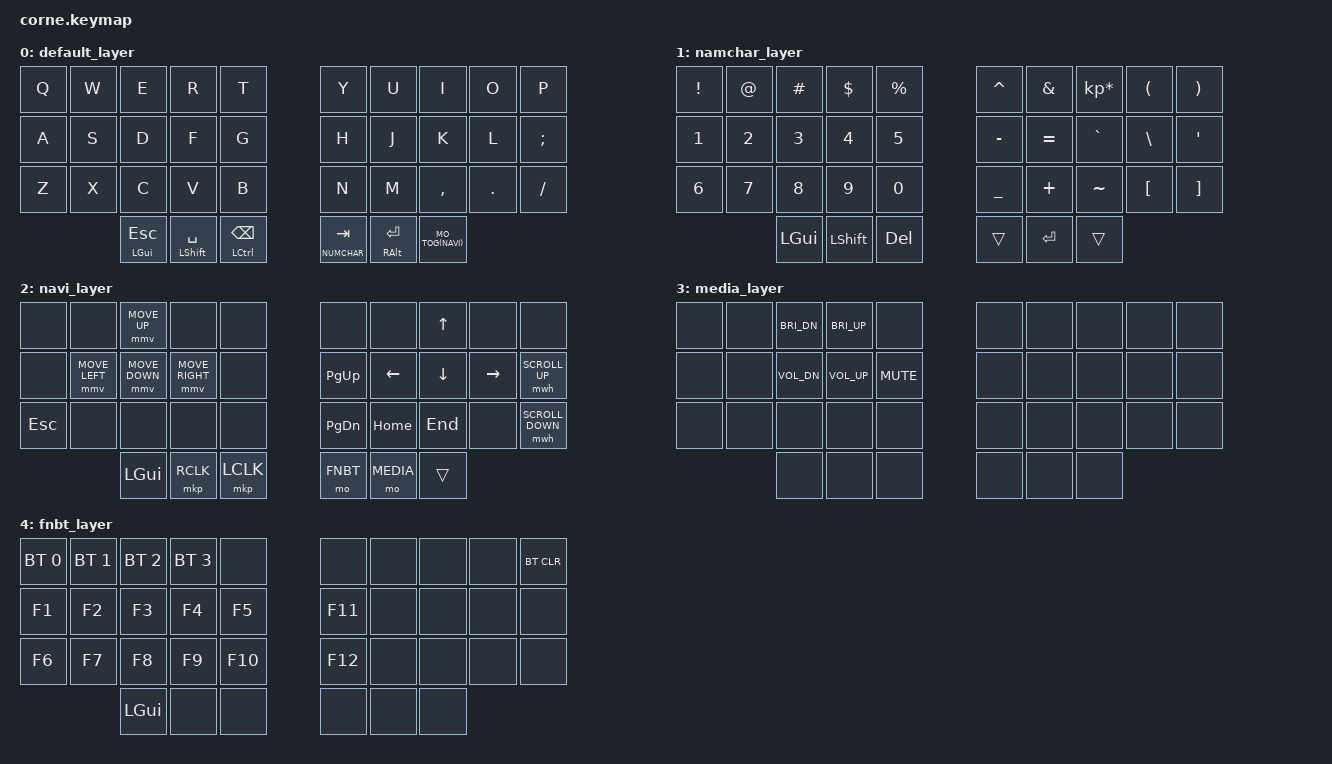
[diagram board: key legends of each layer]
/*
 * Copyright (c) 2020 The ZMK Contributors
 *
 * SPDX-License-Identifier: MIT
 */

#include <behaviors.dtsi>
#include <dt-bindings/zmk/keys.h>
#include <dt-bindings/zmk/bt.h>
#include <dt-bindings/zmk/mouse.h>

#define DEFAULT 0
#define NUMCHAR 1
#define NAVI 2
#define MEDIA 3
#define FNBT 4

#define U_MOUSE_MOVE_MAX 1400
#undef MOVE_UP
#undef MOVE_DOWN
#undef MOVE_LEFT
#undef MOVE_RIGHT
#define MOVE_UP MOVE_VERT(-U_MOUSE_MOVE_MAX)
#define MOVE_DOWN MOVE_VERT(U_MOUSE_MOVE_MAX)
#define MOVE_LEFT MOVE_HOR(-U_MOUSE_MOVE_MAX)
#define MOVE_RIGHT MOVE_HOR(U_MOUSE_MOVE_MAX)

&mmv {
	time-to-max-speed-ms = <400>;
};

#define U_MOUSE_SCROLL_MAX 50

#undef SCROLL_UP
#undef SCROLL_DOWN
#undef SCROLL_LEFT
#undef SCROLL_RIGHT
#define SCROLL_UP SCROLL_VERT(U_MOUSE_SCROLL_MAX)
#define SCROLL_DOWN SCROLL_VERT(-U_MOUSE_SCROLL_MAX)
#define SCROLL_LEFT SCROLL_HOR(-U_MOUSE_SCROLL_MAX)
#define SCROLL_RIGHT SCROLL_HOR(U_MOUSE_SCROLL_MAX)

&mwh {
  time-to-max-speed-ms = <500>;
};

#define MO_TOG(layer) &mo_tog layer layer   // Macro to apply momentary-layer-on-hold/toggle-layer-on-tap to a specific layer

/ {
    behaviors {
        mo_tog: behavior_mo_tog {
            compatible = "zmk,behavior-hold-tap";
            label = "mo_tog";
            #binding-cells = <2>;
            flavor = "hold-preferred";
            tapping-term-ms = <200>;
            bindings = <&mo>, <&tog>;
        };
    };
};

/ {
    chosen {
        zmk,matrix_transform = &five_column_transform;
    };
        keymap {
                compatible = "zmk,keymap";

                default_layer {
// -----------------------------------------------------------------------------------------
// |  Q  |  W  |  E  |  R  |  T  |   |  Y  |  U   |  I  |  O  |  P  |
// |  A  |  S  |  D  |  F  |  G  |   |  H  |  J   |  K  |  L  |  ;  |
// |  Z  |  X  |  C  |  V  |  B  |   |  N  |  M   |  ,  |  .  |  /  |
//                    | GUI | SPC | BKSP |   | ENT | RSE  | ALT |
                        bindings = <
   &kp Q &kp W &kp E &kp R &kp T   &kp Y &kp U  &kp I     &kp O   &kp P
   &kp A &kp S &kp D &kp F &kp G   &kp H &kp J  &kp K     &kp L   &kp SEMI
   &kp Z &kp X &kp C &kp V &kp B   &kp N &kp M  &kp COMMA &kp DOT &kp FSLH
                        &mt LGUI ESC &mt LSHFT SPACE &mt LCTRL BKSP   &lt NUMCHAR TAB &mt RALT RET MO_TOG(NAVI)
                        >;
                };
                namchar_layer {
// -----------------------------------------------------------------------------------------
// |  !  |  @  |  #  |  $  |  %  |   |  ^  |  &  |  *  |  (  |  )  |
// |  1  |  2  |  3  |  4  |  5  |   |  -  |  =  |  `  |  \  |  '  |
// |  6  |  7  |  8  |  9  |  0  |   |  _  |  +  |  ~  |  [  |  ]  |
//                    | GUI | SPC | DEL |   |  | RET | ALT |
                        bindings = <
   &kp EXCL &kp AT &kp HASH &kp DLLR &kp PRCNT  &kp CARET &kp AMPS  &kp KP_MULTIPLY &kp LPAR &kp RPAR
   &kp N1   &kp N2 &kp N3   &kp N4   &kp N5     &kp MINUS &kp EQUAL &kp GRAVE       &kp BSLH &kp SQT
   &kp N6   &kp N7 &kp N8   &kp N9   &kp N0     &kp UNDER &kp PLUS  &kp TILDE       &kp LBKT &kp RBKT
                                    &kp LGUI    &kp LSHFT       &kp DEL      &trans &kp RET   &trans
                        >;
                };

                navi_layer {
// -----------------------------------------------------------------------------------------
// |     |     | MUP |     |     |   |     |     | UP  |     |     |
// |     |MLFT |MDWN |MRIG |     |   | PGU | LFT | DWN | RIG |     |
// | ESC |     |     |     |     |   | PGD | HOME| END |     |     |
//                    | GUI |     | SPC |   | ENT |     | ALT |
                        bindings = <
   &none   &none          &mmv MOVE_UP   &none           &none  &none     &none    &kp UP   &none     &none
   &none   &mmv MOVE_LEFT &mmv MOVE_DOWN &mmv MOVE_RIGHT &none  &kp PG_UP &kp LEFT &kp DOWN &kp RIGHT &mwh SCROLL_UP
   &kp ESC &none          &none          &none           &none  &kp PG_DN &kp HOME &kp END  &none     &mwh SCROLL_DOWN
                             &kp LGUI &mkp RCLK &mkp LCLK  &mo FNBT &mo MEDIA    &trans
                        >;
                };
                
                media_layer {
// -----------------------------------------------------------------------------------------
// |     |     | BUP | BDN |     |   |     |     |     |     |     |
// |     |     | VUP | VDN | MUT |   |     |     |     |     |     |
// |     |     |     |     |     |   |     |     |     |     |     |
//                    |     |     |     |   |     |     |     |
                        bindings = <
   &none &none &kp C_BRI_DN &kp C_BRI_UP &none       &none &none &none &none &none
   &none &none &kp C_VOL_DN &kp C_VOL_UP &kp K_MUTE  &none &none &none &none &none
   &none &none &none        &none        &none       &none &none &none &none &none
                             &none &none &none   &none &none &none
                        >;
                };

                fnbt_layer {
// -----------------------------------------------------------------------------------------
// | BT0 | BT1 |     |     |     |   |     |     |     |     |BTCLR|
// | F1  | F2  |  F3 |  F4 |  F5 |   | F11 |     |     |     |     |
// | F6  | F7  |  F8 |  F9 |  F10|   | F12 |     |     |     |     |
//                    |     |     |     |   |     |     |     |
                        bindings = <
   &bt BT_SEL 0  &bt BT_SEL 1  &bt BT_SEL 2  &bt BT_SEL 3  &none    &none   &none &none &none &bt BT_CLR
   &kp F1        &kp F2        &kp F3        &kp F4        &kp F5   &kp F11 &none &none &none &none
   &kp F6        &kp F7        &kp F8        &kp F9        &kp F10  &kp F12 &none &none &none &none
                             &kp LGUI &none   &none   &none   &none    &none
                        >;
                };
        };
};
